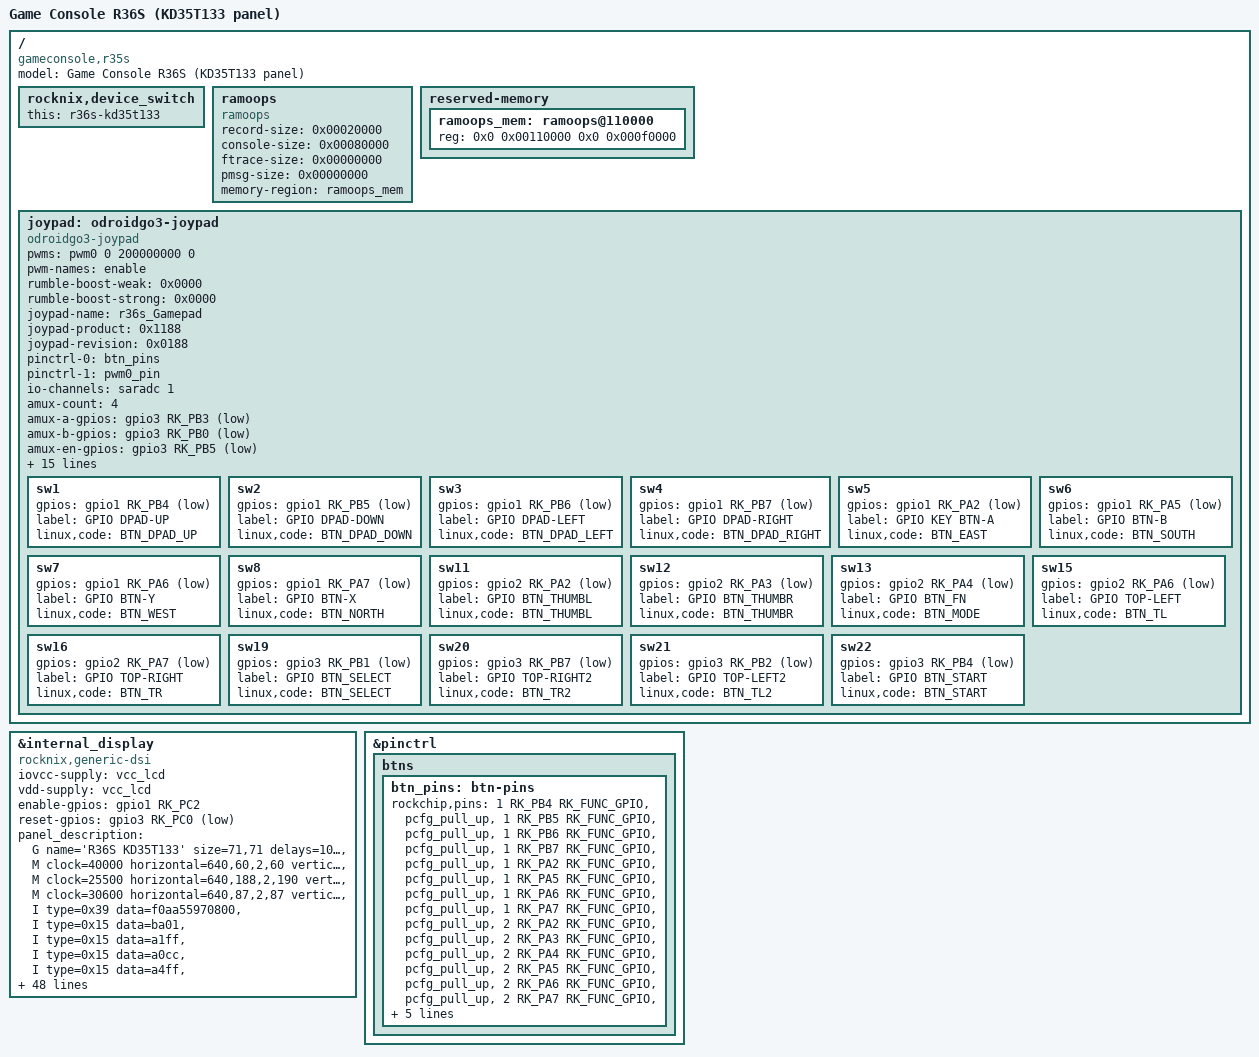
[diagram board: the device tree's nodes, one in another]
// SPDX-License-Identifier: (GPL-2.0+ OR MIT)
/*
 * R36S variant using the KD35T133-compatible panel description extracted
 * from the stock rk3326-r35s-linux.dtb.
 */

/dts-v1/;
#include "rk3326-gameconsole-r3xs.dtsi"
#include "rk3326-device-group-r36.dtsi"

/ {
	model = "Game Console R36S (KD35T133 panel)";
	compatible = "gameconsole,r35s", "gameconsole,r36s", "rockchip,rk3326";

	rocknix,device_switch {
		this = "r36s-kd35t133";
	};

	/* Preserve kernel messages from a failed or crashed previous boot. */
	ramoops {
		compatible = "ramoops";
		record-size = <0x00020000>;
		console-size = <0x00080000>;
		ftrace-size = <0x00000000>;
		pmsg-size = <0x00000000>;
		memory-region = <&ramoops_mem>;
	};

	/* Same reserved region used by the ArkOS stock DTB. */
	reserved-memory {
		#address-cells = <2>;
		#size-cells = <2>;
		ranges;

		ramoops_mem: ramoops@110000 {
			reg = <0x0 0x00110000 0x0 0x000f0000>;
		};
	};

	joypad: odroidgo3-joypad {
		compatible = "odroidgo3-joypad";
		pwms = <&pwm0 0 200000000 0>;
		pwm-names = "enable";
		rumble-boost-weak = <0x0000>;
		rumble-boost-strong = <0x0000>;

		joypad-name = "r36s_Gamepad";
		joypad-product = <0x1188>;
		joypad-revision = <0x0188>;

		status = "okay";

		pinctrl-names = "default";
		pinctrl-0 = <&btn_pins>;
		pinctrl-1 = <&pwm0_pin>;

		io-channel-names = "amux_adc";
		io-channels = <&saradc 1>;

		amux-count = <4>;
		amux-a-gpios = <&gpio3 RK_PB3 GPIO_ACTIVE_LOW>;
		amux-b-gpios = <&gpio3 RK_PB0 GPIO_ACTIVE_LOW>;
		amux-en-gpios = <&gpio3 RK_PB5 GPIO_ACTIVE_LOW>;

		button-adc-scale = <2>;
		button-adc-deadzone = <64>;
		button-adc-fuzz = <32>;
		button-adc-flat = <32>;

		abs_x-p-tuning = <200>;
		abs_x-n-tuning = <200>;
		abs_y-p-tuning = <200>;
		abs_y-n-tuning = <200>;
		abs_rx-p-tuning = <200>;
		abs_rx-n-tuning = <200>;
		abs_ry-p-tuning = <200>;
		abs_ry-n-tuning = <200>;

		poll-interval = <10>;
		invert-absx;
		invert-absy;

		sw1 {
			gpios = <&gpio1 RK_PB4 GPIO_ACTIVE_LOW>;
			label = "GPIO DPAD-UP";
			linux,code = <BTN_DPAD_UP>;
		};
		sw2 {
			gpios = <&gpio1 RK_PB5 GPIO_ACTIVE_LOW>;
			label = "GPIO DPAD-DOWN";
			linux,code = <BTN_DPAD_DOWN>;
		};
		sw3 {
			gpios = <&gpio1 RK_PB6 GPIO_ACTIVE_LOW>;
			label = "GPIO DPAD-LEFT";
			linux,code = <BTN_DPAD_LEFT>;
		};
		sw4 {
			gpios = <&gpio1 RK_PB7 GPIO_ACTIVE_LOW>;
			label = "GPIO DPAD-RIGHT";
			linux,code = <BTN_DPAD_RIGHT>;
		};
		sw5 {
			gpios = <&gpio1 RK_PA2 GPIO_ACTIVE_LOW>;
			label = "GPIO KEY BTN-A";
			linux,code = <BTN_EAST>;
		};
		sw6 {
			gpios = <&gpio1 RK_PA5 GPIO_ACTIVE_LOW>;
			label = "GPIO BTN-B";
			linux,code = <BTN_SOUTH>;
		};
		sw7 {
			gpios = <&gpio1 RK_PA6 GPIO_ACTIVE_LOW>;
			label = "GPIO BTN-Y";
			linux,code = <BTN_WEST>;
		};
		sw8 {
			gpios = <&gpio1 RK_PA7 GPIO_ACTIVE_LOW>;
			label = "GPIO BTN-X";
			linux,code = <BTN_NORTH>;
		};
		sw11 {
			gpios = <&gpio2 RK_PA2 GPIO_ACTIVE_LOW>;
			label = "GPIO BTN_THUMBL";
			linux,code = <BTN_THUMBL>;
		};
		sw12 {
			gpios = <&gpio2 RK_PA3 GPIO_ACTIVE_LOW>;
			label = "GPIO BTN_THUMBR";
			linux,code = <BTN_THUMBR>;
		};
		sw13 {
			gpios = <&gpio2 RK_PA4 GPIO_ACTIVE_LOW>;
			label = "GPIO BTN_FN";
			linux,code = <BTN_MODE>;
		};
		sw15 {
			gpios = <&gpio2 RK_PA6 GPIO_ACTIVE_LOW>;
			label = "GPIO TOP-LEFT";
			linux,code = <BTN_TL>;
		};
		sw16 {
			gpios = <&gpio2 RK_PA7 GPIO_ACTIVE_LOW>;
			label = "GPIO TOP-RIGHT";
			linux,code = <BTN_TR>;
		};
		sw19 {
			gpios = <&gpio3 RK_PB1 GPIO_ACTIVE_LOW>;
			label = "GPIO BTN_SELECT";
			linux,code = <BTN_SELECT>;
		};
		sw20 {
			gpios = <&gpio3 RK_PB7 GPIO_ACTIVE_LOW>;
			label = "GPIO TOP-RIGHT2";
			linux,code = <BTN_TR2>;
		};
		sw21 {
			gpios = <&gpio3 RK_PB2 GPIO_ACTIVE_LOW>;
			label = "GPIO TOP-LEFT2";
			linux,code = <BTN_TL2>;
		};
		sw22 {
			gpios = <&gpio3 RK_PB4 GPIO_ACTIVE_LOW>;
			label = "GPIO BTN_START";
			linux,code = <BTN_START>;
		};
	};
};

&internal_display {
	compatible = "rocknix,generic-dsi";
	iovcc-supply = <&vcc_lcd>;
	vdd-supply = <&vcc_lcd>;
	enable-gpios = <&gpio1 RK_PC2 GPIO_ACTIVE_HIGH>;
	reset-gpios = <&gpio3 RK_PC0 GPIO_ACTIVE_LOW>;

	/* Extracted from the DarkOS DTB running successfully on this panel. */
	panel_description =
		/*
		 * Exact power/DCS lifecycle from the ArkOS KD35T133 DTB.
		 * `dcs=manual` prevents generic-dsi from appending duplicate
		 * Display On / Sleep Out commands after this sequence.
		 */
		"G name='R36S KD35T133' size=71,71 delays=100,50,20,200,50,20 format=rgb888 lanes=4 flags=0xa03 dcs=manual",
		"M clock=40000 horizontal=640,60,2,60 vertical=480,20,4,14 default=1",
		"M clock=25500 horizontal=640,188,2,190 vertical=480,13,2,5",
		"M clock=30600 horizontal=640,87,2,87 vertical=480,13,2,5",
		"I type=0x39 data=f0aa55970800",
		"I type=0x15 data=ba01", "I type=0x15 data=a1ff",
		"I type=0x15 data=a0cc", "I type=0x15 data=a4ff",
		"I type=0x15 data=a50b", "I type=0x15 data=937a",
		"I type=0x15 data=b602", "I type=0x15 data=9daa",
		"I type=0x15 data=e495",
		"I type=0x39 data=f0aa55970801",
		"I type=0x15 data=6006", "I type=0x15 data=62c8",
		"I type=0x15 data=6362", "I type=0x15 data=6580",
		"I type=0x15 data=6689", "I type=0x15 data=6891",
		"I type=0x15 data=69c3", "I type=0x15 data=60ff",
		"I type=0x15 data=61ff", "I type=0x15 data=62ff",
		"I type=0x15 data=63ff", "I type=0x15 data=64ff",
		"I type=0x15 data=65ff", "I type=0x15 data=66ff",
		"I type=0x15 data=67ff", "I type=0x15 data=68ff",
		"I type=0x15 data=69ff",
		"I type=0x39 data=e35a87",
		"I type=0x15 data=cf2d", "I type=0x15 data=e951",
		"I type=0x39 data=b33f3434342829090b0d0f013f34343f3f3f3f3f3f3f3f3f3434342829080a0c0e003f34343f3f3f3f3f3f3f3f",
		"I type=0x39 data=a01805525218045252",
		"I type=0x39 data=a71152525252",
		"I type=0x39 data=a8000301fb00000401fc030300",
		"I type=0x39 data=a9080301f500080201f5030300",
		"I type=0x39 data=aa080101f700080001f8030300",
		"I type=0x39 data=ab000101f900000201fa030300",
		"I type=0x39 data=a400080f080a0000",
		"I type=0x39 data=a611ff880611ff8806",
		"I type=0x39 data=b0222222222222f4",
		"I type=0x15 data=b727",
		"I type=0x39 data=f17f6d615657484c354c4948644f574b45382600",
		"I type=0x39 data=f27f6d615657484c354c4948644f574b45382600",
		"I type=0x39 data=e710027f0000",
		"I type=0x15 data=ed02", "I type=0x15 data=ee22",
		"I type=0x39 data=e6e835", "I type=0x15 data=3500",
		"I type=0x05 data=11 wait=150",
		"I type=0x05 data=29 wait=50",
		"E type=0x05 data=28 wait=20",
		"E type=0x05 data=10 wait=10";
};

&pinctrl {
	btns {
		btn_pins: btn-pins {
			rockchip,pins = <1 RK_PB4 RK_FUNC_GPIO &pcfg_pull_up>,
					<1 RK_PB5 RK_FUNC_GPIO &pcfg_pull_up>,
					<1 RK_PB6 RK_FUNC_GPIO &pcfg_pull_up>,
					<1 RK_PB7 RK_FUNC_GPIO &pcfg_pull_up>,
					<1 RK_PA2 RK_FUNC_GPIO &pcfg_pull_up>,
					<1 RK_PA5 RK_FUNC_GPIO &pcfg_pull_up>,
					<1 RK_PA6 RK_FUNC_GPIO &pcfg_pull_up>,
					<1 RK_PA7 RK_FUNC_GPIO &pcfg_pull_up>,
					<2 RK_PA2 RK_FUNC_GPIO &pcfg_pull_up>,
					<2 RK_PA3 RK_FUNC_GPIO &pcfg_pull_up>,
					<2 RK_PA4 RK_FUNC_GPIO &pcfg_pull_up>,
					<2 RK_PA5 RK_FUNC_GPIO &pcfg_pull_up>,
					<2 RK_PA6 RK_FUNC_GPIO &pcfg_pull_up>,
					<2 RK_PA7 RK_FUNC_GPIO &pcfg_pull_up>,
					<3 RK_PB1 RK_FUNC_GPIO &pcfg_pull_up>,
					<3 RK_PB2 RK_FUNC_GPIO &pcfg_pull_up>,
					<3 RK_PB4 RK_FUNC_GPIO &pcfg_pull_up>,
					<3 RK_PB7 RK_FUNC_GPIO &pcfg_pull_up>;
		};
	};
};
